AUTOSAR XML (schema 314)
package /ComponentType
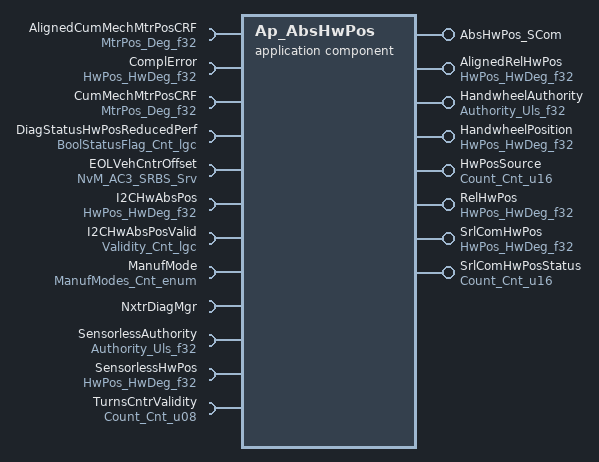
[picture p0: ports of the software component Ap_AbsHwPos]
  application software component type Ap_AbsHwPos
    8 x provide port:
      AbsHwPos_SCom: provided-interface=AbsHwPos_SCom
        provided-com-specs:
          operation=CustClrTrim, queue-length=1
          operation=CustSetTrim, queue-length=1
          operation=NxtClearTrim, queue-length=1
          operation=NxtSetTrim, queue-length=1
      AlignedRelHwPos: unqueued-sender-com-spec{data-element=HwDeg_f32, can-invalidate=false, init-value=D_ZERO_ULS_F32}, provided-interface=HwPos_HwDeg_f32
      HandwheelAuthority: unqueued-sender-com-spec{data-element=Uls_f32, can-invalidate=false, init-value=D_ZERO_ULS_F32}, provided-interface=Authority_Uls_f32
      HandwheelPosition: unqueued-sender-com-spec{data-element=HwDeg_f32, can-invalidate=false, init-value=D_ZERO_ULS_F32}, provided-interface=HwPos_HwDeg_f32
      HwPosSource: unqueued-sender-com-spec{data-element=Cnt_u16, can-invalidate=false, init-value=D_ZERO_CNT_U16}, provided-interface=Count_Cnt_u16
      RelHwPos: unqueued-sender-com-spec{data-element=HwDeg_f32, can-invalidate=false, init-value=D_ZERO_ULS_F32}, provided-interface=HwPos_HwDeg_f32
      SrlComHwPos: unqueued-sender-com-spec{data-element=HwDeg_f32, can-invalidate=false, init-value=D_ZERO_ULS_F32}, provided-interface=HwPos_HwDeg_f32
      SrlComHwPosStatus: unqueued-sender-com-spec{data-element=Cnt_u16, can-invalidate=false, init-value=D_ZERO_CNT_U16}, provided-interface=Count_Cnt_u16
    12 x require port:
      AlignedCumMechMtrPosCRF: unqueued-receiver-com-spec{data-element=Deg_f32, init-value=D_ZERO_ULS_F32}, required-interface=MtrPos_Deg_f32
      ComplError: unqueued-receiver-com-spec{data-element=HwDeg_f32, init-value=D_ZERO_ULS_F32}, required-interface=HwPos_HwDeg_f32
      CumMechMtrPosCRF: unqueued-receiver-com-spec{data-element=Deg_f32, init-value=D_ZERO_ULS_F32}, required-interface=MtrPos_Deg_f32
      DiagStatusHwPosReducedPerf: unqueued-receiver-com-spec{data-element=Cnt_lgc, init-value=D_FALSE_CNT_LGC}, required-interface=BoolStatusFlag_Cnt_lgc
      EOLVehCntrOffset: required-com-specs=[EraseBlock, GetErrorStatus, InvalidateNvBlock, ReadBlock, SetRamBlockStatus, WriteBlock], required-interface=NvM_AC3_SRBS_Srv
      I2CHwAbsPos: unqueued-receiver-com-spec{data-element=HwDeg_f32, init-value=D_ZERO_ULS_F32}, required-interface=HwPos_HwDeg_f32
      I2CHwAbsPosValid: unqueued-receiver-com-spec{data-element=Cnt_lgc, init-value=D_FALSE_CNT_LGC}, required-interface=Validity_Cnt_lgc
      ManufMode: unqueued-receiver-com-spec{data-element=Cnt_enum, init-value=D_MANUFMODEINIT_CNT_ENUM}, required-interface=ManufModes_Cnt_enum
      NxtrDiagMgr: required-com-specs=[GetNTCActive, GetNTCFailed, GetNTCStatus, SetNTCStatus], required-interface=NxtrDiagMgr
      SensorlessAuthority: unqueued-receiver-com-spec{data-element=Uls_f32, init-value=D_ZERO_ULS_F32}, required-interface=Authority_Uls_f32
      SensorlessHwPos: unqueued-receiver-com-spec{data-element=HwDeg_f32, init-value=D_ZERO_ULS_F32}, required-interface=HwPos_HwDeg_f32
      TurnsCntrValidity: unqueued-receiver-com-spec{data-element=Cnt_u08, init-value=D_ZERO_CNT_U8}, required-interface=Count_Cnt_u08
  internal behavior Ap_AbsHwPos_InternalBehavior: component=Ap_AbsHwPos
    5 x timing event:
      AbsHwPos_Init1_InitEvent: start-on-event=AbsHwPos_Init1, period=0
      TMT_AbsHwPos_Per1: start-on-event=AbsHwPos_Per1, period=0.002
      TMT_AbsHwPos_Per2: start-on-event=AbsHwPos_Per2, period=0.002
      TMT_AbsHwPos_Per3: start-on-event=AbsHwPos_Per3, period=0.004
      TMT_AbsHwPos_Per4: start-on-event=AbsHwPos_Per4, period=0.01
    4 x operation invoked event:
      OIT_AbsHwPos_SCom_CustClrTrim_AbsHwPos_SCom_CustClrTrim: start-on-event=AbsHwPos_SCom_CustClrTrim, operation=AbsHwPos_SCom.CustClrTrim
      OIT_AbsHwPos_SCom_CustSetTrim_AbsHwPos_SCom_CustSetTrim: start-on-event=AbsHwPos_SCom_CustSetTrim, operation=AbsHwPos_SCom.CustSetTrim
      OIT_AbsHwPos_SCom_NxtClearTrim_AbsHwPos_SCom_NxtClearTrim: start-on-event=AbsHwPos_SCom_NxtClearTrim, operation=AbsHwPos_SCom.NxtClearTrim
      OIT_AbsHwPos_SCom_NxtSetTrim_AbsHwPos_SCom_NxtSetTrim: start-on-event=AbsHwPos_SCom_NxtSetTrim, operation=AbsHwPos_SCom.NxtSetTrim
    per instance memory EOLVehCntrOffset: type=EOLHwPosTrimType, type-definition=/DataType/EOLHwPosTrimType
    port-api-options:
      enable-take-address=false, indirect-api=false, port=AbsHwPos_SCom
      enable-take-address=false, indirect-api=false, port=AlignedCumMechMtrPosCRF
      enable-take-address=false, indirect-api=false, port=AlignedRelHwPos
      enable-take-address=false, indirect-api=false, port=ComplError
      enable-take-address=false, indirect-api=false, port=CumMechMtrPosCRF
      enable-take-address=false, indirect-api=false, port=DiagStatusHwPosReducedPerf
      enable-take-address=false, indirect-api=false, port=EOLVehCntrOffset
      enable-take-address=false, indirect-api=false, port=HandwheelAuthority
      enable-take-address=false, indirect-api=false, port=HandwheelPosition
      enable-take-address=false, indirect-api=false, port=HwPosSource
      enable-take-address=false, indirect-api=false, port=I2CHwAbsPos
      enable-take-address=false, indirect-api=false, port=I2CHwAbsPosValid
      enable-take-address=false, indirect-api=false, port=ManufMode
      enable-take-address=false, indirect-api=false, port=NxtrDiagMgr
      enable-take-address=false, indirect-api=false, port=RelHwPos
      enable-take-address=false, indirect-api=false, port=SensorlessAuthority
      enable-take-address=false, indirect-api=false, port=SensorlessHwPos
      enable-take-address=false, indirect-api=false, port=SrlComHwPos
      enable-take-address=false, indirect-api=false, port=SrlComHwPosStatus
      enable-take-address=false, indirect-api=false, port=TurnsCntrValidity
    9 x runnable:
      AbsHwPos_Init1
        data read access READ_ManufMode_Cnt_enum: data-element=ManufMode.Cnt_enum
        data write access WRITE_HwPosSource_Cnt_u16: data-element=HwPosSource.Cnt_u16
        data write access WRITE_SrlComHwPosStatus_Cnt_u16: data-element=SrlComHwPosStatus.Cnt_u16
      AbsHwPos_Per1
        data read access READ_AlignedCumMechMtrPosCRF_Deg_f32: data-element=AlignedCumMechMtrPosCRF.Deg_f32
        data read access READ_ComplError_HwDeg_f32: data-element=ComplError.HwDeg_f32
        data read access READ_CumMechMtrPosCRF_Deg_f32: data-element=CumMechMtrPosCRF.Deg_f32
        data write access WRITE_AlignedRelHwPos_HwDeg_f32: data-element=AlignedRelHwPos.HwDeg_f32
        data write access WRITE_RelHwPos_HwDeg_f32: data-element=RelHwPos.HwDeg_f32
      AbsHwPos_Per2
        7 x data read access:
          READ_DiagStatusHwPosReducedPerf_Cnt_lgc: data-element=DiagStatusHwPosReducedPerf.Cnt_lgc
          READ_I2CHwAbsPos_HwDeg_f32: data-element=I2CHwAbsPos.HwDeg_f32
          READ_I2CHwAbsPosValid_Cnt_lgc: data-element=I2CHwAbsPosValid.Cnt_lgc
          READ_ManufMode_Cnt_enum: data-element=ManufMode.Cnt_enum
          READ_SensorlessAuthority_Uls_f32: data-element=SensorlessAuthority.Uls_f32
          READ_SensorlessHwPos_HwDeg_f32: data-element=SensorlessHwPos.HwDeg_f32
          READ_TurnsCntrValidity_Cnt_u08: data-element=TurnsCntrValidity.Cnt_u08
        5 x data write access:
          WRITE_HandwheelAuthority_Uls_f32: data-element=HandwheelAuthority.Uls_f32
          WRITE_HandwheelPosition_HwDeg_f32: data-element=HandwheelPosition.HwDeg_f32
          WRITE_HwPosSource_Cnt_u16: data-element=HwPosSource.Cnt_u16
          WRITE_SrlComHwPos_HwDeg_f32: data-element=SrlComHwPos.HwDeg_f32
          WRITE_SrlComHwPosStatus_Cnt_u16: data-element=SrlComHwPosStatus.Cnt_u16
        sync call SC_EOLVehCntrOffset_GetErrorStatus: operation=EOLVehCntrOffset.GetErrorStatus, timeout=0
        sync call SC_EOLVehCntrOffset_WriteBlock: operation=EOLVehCntrOffset.WriteBlock, timeout=0
      AbsHwPos_Per3
        data read access READ_I2CHwAbsPos_HwDeg_f32: data-element=I2CHwAbsPos.HwDeg_f32
        data read access READ_I2CHwAbsPosValid_Cnt_lgc: data-element=I2CHwAbsPosValid.Cnt_lgc
        sync call SC_NxtrDiagMgr_SetNTCStatus: operation=NxtrDiagMgr.SetNTCStatus, timeout=0
      AbsHwPos_Per4
        sync call SC_NxtrDiagMgr_SetNTCStatus: operation=NxtrDiagMgr.SetNTCStatus, timeout=0
      AbsHwPos_SCom_CustClrTrim
        data receive point REC_ManufMode_Cnt_enum: data-element=ManufMode.Cnt_enum
        sync call SC_EOLVehCntrOffset_WriteBlock: operation=EOLVehCntrOffset.WriteBlock, timeout=0
        sync call SC_NxtrDiagMgr_SetNTCStatus: operation=NxtrDiagMgr.SetNTCStatus, timeout=0
      AbsHwPos_SCom_CustSetTrim
        data receive point REC_ManufMode_Cnt_enum: data-element=ManufMode.Cnt_enum
        data receive point REC_TurnsCntrValidity_Cnt_u08: data-element=TurnsCntrValidity.Cnt_u08
        sync call SC_EOLVehCntrOffset_WriteBlock: operation=EOLVehCntrOffset.WriteBlock, timeout=0
        sync call SC_NxtrDiagMgr_SetNTCStatus: operation=NxtrDiagMgr.SetNTCStatus, timeout=0
      AbsHwPos_SCom_NxtClearTrim
        sync call SC_EOLVehCntrOffset_WriteBlock: operation=EOLVehCntrOffset.WriteBlock, timeout=0
      AbsHwPos_SCom_NxtSetTrim
        data receive point REC_TurnsCntrValidity_Cnt_u08: data-element=TurnsCntrValidity.Cnt_u08
        sync call SC_EOLVehCntrOffset_WriteBlock: operation=EOLVehCntrOffset.WriteBlock, timeout=0
    service-needss:
      swc nv block needs EOLVehCntrOffsetBlock: n-data-sets=0, readonly=false, reliability=LOW, resistant-to-changed-sw=false, restore-at-start=false, write-only-once=false, writing-frequency=0, writing-priority=LOW, mirror-block=EOLVehCntrOffset
  swc implementation Ap_AbsHwPos_Implementation: behavior=Ap_AbsHwPos_InternalBehavior
    code-descriptors:
      code Code: type=SRC
